# ISD91200B_v1 register map
File version: 1.0
Registers are 32-bit, read-write, reset 0x0 unless marked. A register's access mark holds for its fields unless they carry their own. Offsets are from the block's base; [hi:lo] are bit positions; {n}, {i} and the like mark numbered series.

## BIQ — BIQ Register Map
Base 0x400B0000
{0x0+4i} BIQ_COEFF{i} (i=0..2) — Coefficient B{i} in H(z) Transfer Function (3.16 Format) - 1st Stage BIQ Coefficients
  [31:0] COEFFDAT — Coefficient Data
0x0C BIQ_COEFF3 — Coefficient A1 in H(z) Transfer Function (3.16 Format) - 1st Stage BIQ Coefficients
  [31:0] COEFFDAT — Coefficient Data
0x10 BIQ_COEFF4 — Coefficient A2 in H(z) Transfer Function (3.16 Format) - 1st Stage BIQ Coefficients
  [31:0] COEFFDAT — Coefficient Data
{0x0+4i} BIQ_COEFF{i} (i=5..7) — Coefficient B{i-5} in H(z) Transfer Function (3.16 Format) - 2nd Stage BIQ Coefficients
  [31:0] COEFFDAT — Coefficient Data
0x20 BIQ_COEFF8 — Coefficient A1 in H(z) Transfer Function (3.16 Format) - 2nd Stage BIQ Coefficients
  [31:0] COEFFDAT — Coefficient Data
0x24 BIQ_COEFF9 — Coefficient A2 in H(z) Transfer Function (3.16 Format) - 2nd Stage BIQ Coefficients
  [31:0] COEFFDAT — Coefficient Data
{0x0+4i} BIQ_COEFF{i} (i=10..12) — Coefficient B{i-10} in H(z) Transfer Function (3.16 Format) - 3rd Stage BIQ Coefficients
  [31:0] COEFFDAT — Coefficient Data
0x34 BIQ_COEFF13 — Coefficient A1 in H(z) Transfer Function (3.16 Format) - 3rd Stage BIQ Coefficients
  [31:0] COEFFDAT — Coefficient Data
0x38 BIQ_COEFF14 — Coefficient A2 in H(z) Transfer Function (3.16 Format) - 3rd Stage BIQ Coefficients
  [31:0] COEFFDAT — Coefficient Data
{0x0+4i} BIQ_COEFF{i} (i=15..17) — Coefficient B{i-15} in H(z) Transfer Function (3.16 Format) - 4st Stage BIQ Coefficients
  [31:0] COEFFDAT — Coefficient Data
0x48 BIQ_COEFF18 — Coefficient A1 in H(z) Transfer Function (3.16 Format) - 4st Stage BIQ Coefficients
  [31:0] COEFFDAT — Coefficient Data
0x4C BIQ_COEFF19 — Coefficient A2 in H(z) Transfer Function (3.16 Format) - 4st Stage BIQ Coefficients
  [31:0] COEFFDAT — Coefficient Data
{0x0+4i} BIQ_COEFF{i} (i=20..22) — Coefficient B{i-20} in H(z) Transfer Function (3.16 Format) - 5nd Stage BIQ Coefficients
  [31:0] COEFFDAT — Coefficient Data
0x5C BIQ_COEFF23 — Coefficient A1 in H(z) Transfer Function (3.16 Format) - 5nd Stage BIQ Coefficients
  [31:0] COEFFDAT — Coefficient Data
0x60 BIQ_COEFF24 — Coefficient A2 in H(z) Transfer Function (3.16 Format) - 5nd Stage BIQ Coefficients
  [31:0] COEFFDAT — Coefficient Data
{0x0+4i} BIQ_COEFF{i} (i=25..27) — Coefficient B{i-25} in H(z) Transfer Function (3.16 Format) - 6rd Stage BIQ Coefficients
  [31:0] COEFFDAT — Coefficient Data
0x70 BIQ_COEFF28 — Coefficient A1 in H(z) Transfer Function (3.16 Format) - 6rd Stage BIQ Coefficients
  [31:0] COEFFDAT — Coefficient Data
0x74 BIQ_COEFF29 — Coefficient A2 in H(z) Transfer Function (3.16 Format) - 6rd Stage BIQ Coefficients
  [31:0] COEFFDAT — Coefficient Data
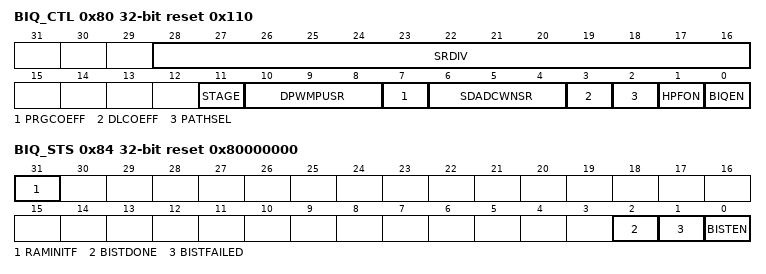
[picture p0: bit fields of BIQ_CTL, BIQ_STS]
0x80 BIQ_CTL reset 0x110 — BIQ Control Register
  [28:16] SRDIV — SR Divider
  [11] STAGE — BIQ Stage Number Control
    0=6 stage; 1=5 stage
  [10:8] DPWMPUSR — DPWM Path Up Sample Rate (From SRDIV Result). 0001 --- up 1x ( no up sample). 0010 --- up 2x. 0011 --- up 3x. 0100 --- up 4x. 0110 --- up 6x. Others reserved
  [7] PRGCOEFF — Programming Mode Coefficient Control Bit. This bit must be turned off when BIQEN is on.
    0=Coefficient RAM is in normal mode; 1=coefficient RAM is under programming mode
  [6:4] SDADCWNSR — SDADC Down Sample. 001--- 1x (no down sample). 010 --- 2x. 011 --- 3x. 100 --- 4x. 11 0--- 6x. Others reserved
  [3] DLCOEFF — Move BIQ Out of Reset State
    0=BIQ filter is in reset state; 1=When this bit is on, the default coefficients will be downloaded to the coefficient ram automatically in 32 internal system clocks. Processor must delay enough time before changing the coefficients or turn the BIQ on
  [2] PATHSEL — AC Path Selection for BIQ
    0=used in SDADC path; 1=used in DPWM path
  [1] HPFON — High Pass Filter On. Note : If this register is on, BIQ only 5 stage left.for user. SDADC path sixth stage coefficient is for HPF filter coefficient. DPWM path first stage coefficient is for HPF filter coefficient.
    0=disable high pass filter; 1=enable high pass filter
  [0] BIQEN — BIQ Filter Start to Run
    0=BIQ filter is not processing; 1=BIQ filter is on
0x84 BIQ_STS reset 0x80000000 — BIQ Status Register
  [31] RAMINITF — Coefficient Ram Initial Default Done Flag
    0=initial default value done; 1=still working on
  [2] BISTDONE — RAM BIST testing DONE flag for internal use
  [1] BISTFAILED — RAM BIST testing FAILED indicator for internal use
  [0] BISTEN — RAM BIST testing Enable for internal use
